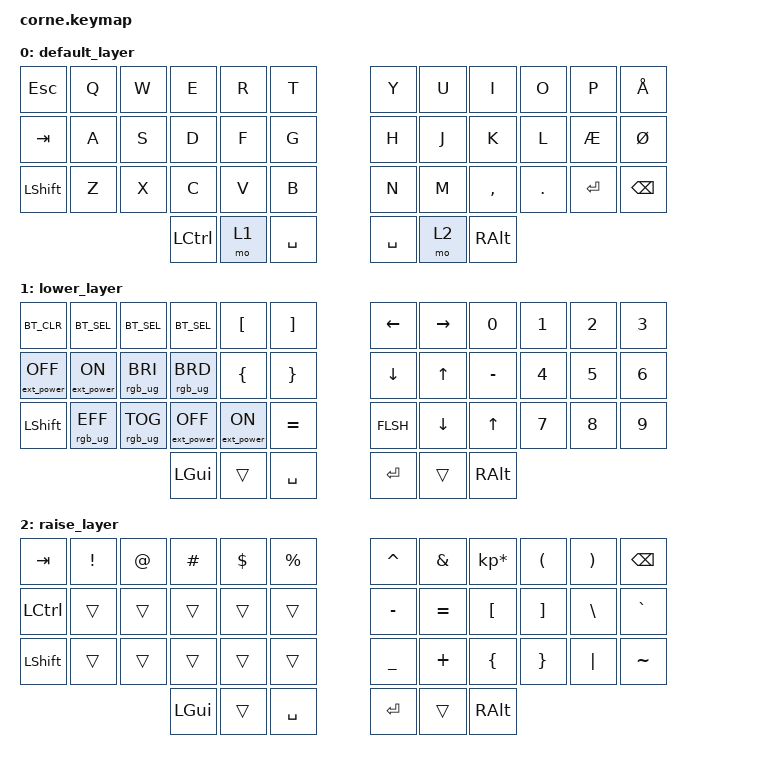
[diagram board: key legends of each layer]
/*
 * Copyright (c) 2020 The ZMK Contributors
 *
 * SPDX-License-Identifier: MIT
 */

#include <behaviors.dtsi>
#include <dt-bindings/zmk/keys.h>
#include <dt-bindings/zmk/bt.h>

/ {
        keymap {
                compatible = "zmk,keymap";

                default_layer {
// -----------------------------------------------------------------------------------------
// | ESC |  Q  |  W  |  E  |  R  |  T  |   |  Y  |  U   |  I  |  O  |  P  | Å |
// | TAB |  A  |  S  |  D  |  F  |  G  |   |  H  |  J   |  K  |  L  |  Æ  |  Ø   |
// | SHFT |  Z  |  X  |  C  |  V  |  B  |   |  N  |  M   |  ,  |  .  |  ENT  | BKSP  |
//                    | CTRL | LWR | SPC |   | SPC | RSE  | ALT |
                        bindings = <
   &kp ESC &kp Q &kp W &kp E &kp R &kp T   &kp Y &kp U &kp I &kp O &kp P &kp Å
   &kp TAB &kp A &kp S &kp D &kp F &kp G   &kp H &kp J &kp K  &kp L &kp Æ &kp Ø
   &kp LSHFT &kp Z &kp X &kp C &kp V &kp B   &kp N &kp M  &kp COMMA &kp DOT &kp RET &kp BSPC
                  &kp LCTRL &mo 1 &kp SPACE   &kp SPACE &mo 2 &kp RALT
                        >;
                };
                 lower_layer {
// -----------------------------------------------------------------------------------------
// | BTCLR | BT1 | BT2 | BT3         | [ | ] |           | LFT | RGT | 0 | 1 | 2 | 3 |
// | EPOn| EPOFF | RGB_BRI | RGB_BRD | { | } |            | DWN | UP | - | 4 | 5 | 6 |
// | SHFT |||                        | [ | ] |               | = | / | * | 7 | 8 | 9 |
//                    | GUI |     | SPC |   | ENT |     | ALT |
                        bindings = <
   &kp BT_CLR &kp BT_SEL 0 &kp BT_SEL 1 &kp BT_SEL 2 &kp LBKT &kp RBKT                 &kp LEFT &kp RIGHT &kp N0 &kp N1 &kp N2 &kp N3
   &ext_power EP_OFF &ext_power EP_ON &rgb_ug RGB_BRI &rgb_ug RGB_BRD &kp LBRC &kp RBRC         &kp DOWN &kp UP &kp MINUS &kp N4 &kp N5 &kp N6
   &kp LSHFT  &rgb_ug RGB_EFF &rgb_ug RGB_TOG  &ext_power EP_OFF  &ext_power EP_ON     &kp EQUAL &kp FLSH &kp DOWN &kp UP &kp N7 &kp N8 &kp N9
                                    &kp LGUI     &trans       &kp SPACE      &kp RET  &trans   &kp RALT
                        >;
                };

                raise_layer {
// -----------------------------------------------------------------------------------------
// |  TAB |  !  |  @  |  #  |  $  |  %  |   |  ^  |  &  |  *  |  (  |  )  | BKSP |
// | CTRL |     |     |     |     |     |   |  -  |  =  |  [  |  ]  |  \  |  `   |
// | SHFT |     |     |     |     |     |   |  _  |  +  |  {  |  }  | "|" |  ~   |
//                    | GUI |     | SPC |   | ENT |     | ALT |
                        bindings = <
   &kp  TAB  &kp EXCL &kp AT &kp HASH &kp DLLR &kp PRCNT   &kp CARET &kp AMPS  &kp KP_MULTIPLY &kp LPAR &kp RPAR &kp BSPC
   &kp LCTRL &trans   &trans &trans   &trans   &trans      &kp MINUS &kp EQUAL &kp LBKT        &kp RBKT &kp BSLH &kp GRAVE
   &kp LSHFT &trans   &trans &trans   &trans   &trans      &kp UNDER &kp PLUS  &kp LBRC        &kp RBRC &kp PIPE &kp TILDE
                             &kp LGUI &trans   &kp SPACE   &kp RET   &trans    &kp RALT
                        >;
                };
        };
};
